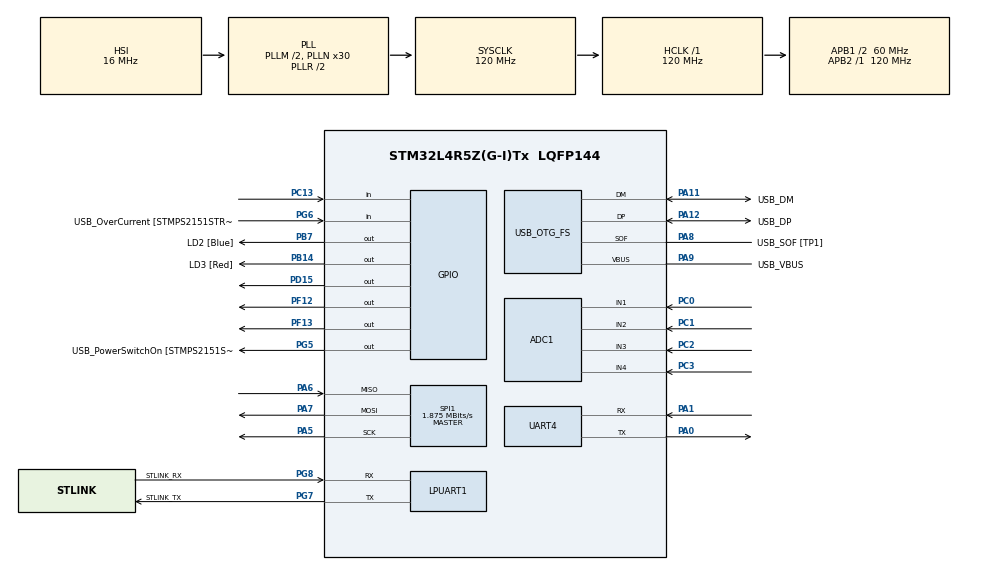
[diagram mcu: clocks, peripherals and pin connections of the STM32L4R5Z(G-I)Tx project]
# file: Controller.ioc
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ADC1.Channel-0\#ChannelRegularConversion=ADC_CHANNEL_1
ADC1.NbrOfConversionFlag=1
ADC1.OffsetNumber-0\#ChannelRegularConversion=ADC_OFFSET_NONE
ADC1.Rank-0\#ChannelRegularConversion=1
ADC1.SamplingTime-0\#ChannelRegularConversion=ADC_SAMPLETIME_2CYCLES_5
ADC1.master=1
Mcu.Family=STM32L4
Mcu.Name=STM32L4R5Z(G-I)Tx
Mcu.Package=LQFP144
NVIC.PriorityGroup=NVIC_PRIORITYGROUP_4
NVIC.TIM3_IRQn=true\:0\:0\:false\:false\:true\:true\:true\:true
PA0.Mode=Asynchronous
PA0.Signal=UART4_TX
PA1.Mode=Asynchronous
PA1.Signal=UART4_RX
PA10.GPIO_Label=USB_ID
PA10.Signal=USB_OTG_FS_ID
PA11.GPIO_Label=USB_DM
PA11.Mode=Device_Only
PA11.Signal=USB_OTG_FS_DM
PA12.GPIO_Label=USB_DP
PA12.Mode=Device_Only
PA12.Signal=USB_OTG_FS_DP
PA13\ (JTMS/SWDIO).GPIO_Label=TMS
PA13\ (JTMS/SWDIO).Mode=Trace_Asynchronous_SW
PA13\ (JTMS/SWDIO).Signal=SYS_JTMS-SWDIO
PA14\ (JTCK/SWCLK).GPIO_Label=TCK
PA14\ (JTCK/SWCLK).Mode=Trace_Asynchronous_SW
PA14\ (JTCK/SWCLK).Signal=SYS_JTCK-SWCLK
PA5.Mode=Full_Duplex_Master
PA5.Signal=SPI1_SCK
PA6.Mode=Full_Duplex_Master
PA6.Signal=SPI1_MISO
PA7.Mode=Full_Duplex_Master
PA7.Signal=SPI1_MOSI
PA8.GPIO_Label=USB_SOF [TP1]
PA8.Mode=Activate_SOF_FS
PA8.Signal=USB_OTG_FS_SOF
PA9.GPIO_Label=USB_VBUS
PA9.Mode=Activate_VBUS
PA9.Signal=USB_OTG_FS_VBUS
PB14.GPIO_Label=LD3 [Red]
PB14.Signal=GPIO_Output
PB3\ (JTDO/TRACESWO).GPIO_Label=SWO
PB3\ (JTDO/TRACESWO).Mode=Trace_Asynchronous_SW
PB3\ (JTDO/TRACESWO).Signal=SYS_JTDO-SWO
PB7.GPIO_Label=LD2 [Blue]
PB7.Signal=GPIO_Output
PC0.Signal=ADCx_IN1
PC1.Signal=ADCx_IN2
PC13.Signal=GPIO_Input
PC14-OSC32_IN\ (PC14).Mode=LSE-External-Oscillator
PC14-OSC32_IN\ (PC14).Signal=RCC_OSC32_IN
PC15-OSC32_OUT\ (PC15).Mode=LSE-External-Oscillator
PC15-OSC32_OUT\ (PC15).Signal=RCC_OSC32_OUT
PC2.Signal=ADCx_IN3
PC3.Signal=ADCx_IN4
PD15.Signal=GPIO_Output
PD8.GPIO_Label=STLK_RX [STM32F103CBT6_PA3]
PD8.Signal=USART3_TX
PD9.GPIO_Label=STLK_TX [STM32F103CBT6_PA2]
PD9.Signal=USART3_RX
PF12.PinState=GPIO_PIN_SET
PF12.Signal=GPIO_Output
PF13.PinState=GPIO_PIN_SET
PF13.Signal=GPIO_Output
PG5.GPIO_Label=USB_PowerSwitchOn [STMPS2151STR_EN]
PG5.Signal=GPIO_Output
PG6.GPIO_Label=USB_OverCurrent [STMPS2151STR_FAULT]
PG6.Signal=GPIO_Input
PG7.GPIO_Label=STLINK_TX
PG7.Mode=Asynchronous
PG7.Signal=LPUART1_TX
PG8.GPIO_Label=STLINK_RX
PG8.Mode=Asynchronous
PG8.Signal=LPUART1_RX
PH0-OSC_IN\ (PH0).Signal=RCC_OSC_IN
PH1-OSC_OUT\ (PH1).Signal=RCC_OSC_OUT
ProjectManager.HeapSize=0x200
ProjectManager.StackSize=0x400
ProjectManager.TargetToolchain=STM32CubeIDE
RCC.48MHZClocksFreq_Value=24000000
RCC.ADCFreq_Value=48000000
RCC.AHBFreq_Value=120000000
RCC.APB1CLKDivider=RCC_HCLK_DIV2
RCC.APB1Freq_Value=60000000
RCC.APB1TimFreq_Value=120000000
RCC.APB2Freq_Value=120000000
RCC.APB2TimFreq_Value=120000000
RCC.CK48CLockSelection=RCC_USBCLKSOURCE_HSI48
RCC.CortexFreq_Value=120000000
RCC.HCLKFreq_Value=120000000
RCC.HSE_VALUE=8000000
RCC.HSI48_VALUE=48000000
RCC.HSI_VALUE=16000000
RCC.MSI_VALUE=4000000
RCC.PLLM1=2
RCC.PLLM2=2
RCC.PLLMUL=RCC_PLL_MUL9
RCC.PLLN=30
RCC.PLLSAI1N=12
RCC.PLLSourceVirtual=RCC_PLLSOURCE_HSI
RCC.PRESCALERUSB=RCC_USBCLKSOURCE_PLL_DIV1_5
RCC.SYSCLKFreq_VALUE=120000000
RCC.SYSCLKSource=RCC_SYSCLKSOURCE_PLLCLK
RCC.SYSCLKSourceVirtual=RCC_SYSCLKSOURCE_PLLCLK
RCC.USBFreq_Value=48000000
RCC.VCOOutputFreq_Value=240000000
SH.ADCx_IN1.0=ADC1_IN1,IN1-Single-Ended
SH.ADCx_IN2.0=ADC1_IN2,IN2-Single-Ended
SH.ADCx_IN3.0=ADC1_IN3,IN3-Single-Ended
SH.ADCx_IN4.0=ADC1_IN4,IN4-Single-Ended
SPI1.BaudRatePrescaler=SPI_BAUDRATEPRESCALER_64
SPI1.CalculateBaudRate=1.875 MBits/s
SPI1.DataSize=SPI_DATASIZE_8BIT
SPI1.Direction=SPI_DIRECTION_2LINES
SPI1.Mode=SPI_MODE_MASTER
SPI1.NSSPMode=SPI_NSS_PULSE_DISABLE
SPI1.VirtualType=VM_MASTER
TIM3.Period=49999
TIM3.Prescaler=8399
UART4.FIFOMode=FIFOMODE_ENABLE
USB_OTG_FS.VirtualMode=Device_Only
VP_TIM3_VS_ClockSourceINT.Mode=Internal
board=NUCLEO-L4R5ZI

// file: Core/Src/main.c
/* USER CODE BEGIN Header */
/**
 ******************************************************************************
 * @file           : main.c
 * @brief          : Main program body
 ******************************************************************************
 * @attention
 *
 * Copyright (c) 2022 STMicroelectronics.
 * All rights reserved.
 *
 * This software is licensed under terms that can be found in the LICENSE file
 * in the root directory of this software component.
 * If no LICENSE file comes with this software, it is provided AS-IS.
 *
 ******************************************************************************
 */
/* USER CODE END Header */
#include "main.h"

/* USER CODE BEGIN Includes */
#include "LCD.h"
#include "TS.h"
#include <stdlib.h>
#include <math.h>
/* USER CODE END Includes */

/* USER CODE BEGIN PD */
#define COL_1			40
#define COL_2 		155
#define COL_3  	 	268
#define ROW_1			204
#define ROW_2			350
#define ROW_3			454
#define ERROR			25
/* USER CODE END PD */

ADC_HandleTypeDef hadc1;

UART_HandleTypeDef hlpuart1;
UART_HandleTypeDef huart4;

SPI_HandleTypeDef hspi1;

TIM_HandleTypeDef htim3;

PCD_HandleTypeDef hpcd_USB_OTG_FS;

/* USER CODE BEGIN PV */
unsigned char goalTemp[3][2];
unsigned char currTemp[3][2];
struct room {
	uint8_t goalTemp;
	uint8_t currTemp;
	uint8_t ID;
}typedef room_t;

void initRoom(room_t *room, int ID, int goalTemp, int currTemp) {
	room->ID = ID;
	room->goalTemp = goalTemp;
	room->currTemp = currTemp;
}

void initDisplay(SPI_HandleTypeDef *spi, room_t *rooms, int count) {
	LCD_writePixels(&hspi1, LCD_color565(255, 255, 255), 0, 0, LCD_WIDTH,
	LCD_HEIGHT);
	for (int i = 0; i < count; ++i) {
		itoa(rooms[i].goalTemp, &goalTemp[i][0], 10);
		itoa(rooms[i].currTemp, &currTemp[i][0], 10);

		int size = 8;
		int start = (LCD_WIDTH / 3) * (rooms[i].ID - 1) + size + 5;

		LCD_drawStringNoBG(spi, start, size, &currTemp[i][0], 2,
				LCD_color565(0, 0, 0), size);
		LCD_drawStringNoBG(spi, start, 9 * size, &goalTemp[i][0], 2,
				LCD_color565(75, 75, 75), size);

		LCD_drawButtonNoBG(&hspi1, start, 18 * size, 0, LCD_color565(255, 0, 0),
				size * 2 + 1);
		LCD_drawButtonNoBG(&hspi1, start, 34 * size, 1, LCD_color565(0, 0, 255),
				size * 2 + 1);
	}
	unsigned char heat[4] = "HEAT";
	unsigned char air[3] = "AIR";
	LCD_writePixels(&hspi1, LCD_color565(0, 0, 0), 6, LCD_HEIGHT - 8 * 6 - 4,
			23 * 6, 2);
	LCD_drawStringNoBG(spi, 6, LCD_HEIGHT - 8 * 6, &heat[0], 4,
			LCD_color565(0, 0, 0), 6);
	LCD_drawStringNoBG(spi, LCD_WIDTH - 18 * 6, LCD_HEIGHT - 8 * 6, &air[0], 3,
			LCD_color565(0, 0, 0), 6);
}

void updateDisplayTemp(SPI_HandleTypeDef *spi, room_t *room) {
	unsigned char buf[2];
	int size = 8;
	int start = (LCD_WIDTH / 3) * (room->ID - 1) + size + 5;

	itoa(room->currTemp, &buf[0], 10);
	if (buf[0] != currTemp[room->ID - 1][0]) {
		LCD_drawStringOPT(spi, start, size, &buf[0], &currTemp[room->ID - 1][0],
				2, LCD_color565(0, 0, 0), size);
		currTemp[room->ID - 1][0] = buf[0];
		currTemp[room->ID - 1][1] = buf[1];
	} else if (buf[1] != currTemp[room->ID - 1][1]) {
		LCD_drawCharOPT(spi, start + 6 * size, size, buf[1],
				currTemp[room->ID - 1][1], LCD_color565(0, 0, 0), size);
		currTemp[room->ID - 1][1] = buf[1];
	}

	itoa(room->goalTemp, &buf[0], 10);
	if (buf[0] != goalTemp[room->ID - 1][0]) {
		LCD_drawStringOPT(spi, start, 9 * size, &buf[0],
				&goalTemp[room->ID - 1][0], 2, LCD_color565(75, 75, 75), size);
		goalTemp[room->ID - 1][0] = buf[0];
		goalTemp[room->ID - 1][1] = buf[1];
	} else if (buf[1] != goalTemp[room->ID - 1][1]) {
		LCD_drawCharOPT(spi, start + 6 * size, 9 * size, buf[1],
				goalTemp[room->ID - 1][1], LCD_color565(75, 75, 75), size);
		goalTemp[room->ID - 1][1] = buf[1];
	}
}

void updateDisplayFurnace(SPI_HandleTypeDef *spi, int furnaceState) {
	int size = 6;
	if (furnaceState) {
		LCD_writePixels(spi, LCD_color565(255, 255, 255), size,
		LCD_HEIGHT - 8 * 6 - 4, 23 * size, 2);
		LCD_writePixels(&hspi1, LCD_color565(0, 0, 0), LCD_WIDTH - 18 * 6,
		LCD_HEIGHT - 8 * 6 - 4, 17 * size, 2);
	} else {
		LCD_writePixels(spi, LCD_color565(0, 0, 0), size,
		LCD_HEIGHT - 8 * 6 - 4, 23 * size, 2);
		LCD_writePixels(&hspi1, LCD_color565(255, 255, 255), LCD_WIDTH - 18 * 6,
		LCD_HEIGHT - 8 * 6 - 4, 17 * size, 2);
	}
}
/* USER CODE END PV */

void SystemClock_Config(void);
static void MX_GPIO_Init(void);
static void MX_LPUART1_UART_Init(void);
static void MX_USB_OTG_FS_PCD_Init(void);
static void MX_ADC1_Init(void);
static void MX_SPI1_Init(void);
static void MX_UART4_Init(void);
static void MX_TIM3_Init(void);

/* USER CODE BEGIN 0 */
uint8_t curr_temp[] = { 0, 0, 0, 0 };
uint8_t desired_temp[] = { 0, 11, 11, 0 };

HAL_StatusTypeDef transmit_status;
HAL_StatusTypeDef receive_status;

int interrupts_disabled = 0;
room_t rooms[3];

/* {0x00000000, 0x00000000} - ([0] => either 0 for desired state command, or a 1 for peripheral current_temp request command),
 *							([1] => first bit is furnace status, next 5 are desired temp, last 2 are vent id) */
uint8_t data_size = 2;
uint8_t received_data_size = 1;
uint8_t send_desired_state = 0x00;
uint8_t receive_current_temp = 0x80;
uint8_t furnace_status_on = 0x80;
uint8_t furnace_status_off = 0x00;
uint8_t vent_id_1 = 0x01;
uint8_t vent_id_2 = 0x02;
uint8_t vent_id_3 = 0x03;
uint8_t vent_ids[] = { 0x00, 0x01, 0x02, 0x03 };

HAL_StatusTypeDef transmit_updated_state(uint8_t data) {
	HAL_StatusTypeDef transmit_status = HAL_UART_Transmit(&huart4, data, 1,
			100);
	return transmit_status;
}

HAL_StatusTypeDef receive_acknowledge(uint8_t *received_data) {
	HAL_StatusTypeDef receive_status = HAL_UART_Receive(&huart4, received_data,
			1, 100);
	return receive_status;
}

void transmit_room_info(uint8_t *received_data, uint8_t room_index) {
	while (receive_acknowledge(received_data) != HAL_OK) {
		uint8_t lower_temp = ((rooms[room_index].goalTemp & 0x0F) << 4) | rooms[room_index].ID;
		transmit_updated_state(lower_temp);
	}
	while (receive_acknowledge(received_data) != HAL_OK) {
		uint8_t upper_temp = (rooms[room_index].goalTemp & 0xF0) | rooms[room_index].ID;
		transmit_updated_state(upper_temp);
	}
	while (receive_acknowledge(received_data) != HAL_OK) {
		transmit_updated_state((furnaceState << 5) | rooms[room_index].ID);
	}
}

//HAL_StatusTypeDef transmit_updated_state(room_t *rooms, int furnace_status) {
//	HAL_StatusTypeDef transmit_status;
//	uint8_t data[] = { send_desired_state, (uint8_t) ((furnace_status << 7)
//			| ((rooms->goalTemp - 55) << 2) | rooms->ID) };
//	for (int j = 0; j < sizeof(data); j++) {
//		transmit_status = HAL_UART_Transmit(&huart4, &(data[j]), 1, 1000);
//	}
//	HAL_Delay(1000);
//	return transmit_status;
//}

/* USER CODE END 0 */

int main(void) {

	/* MCU Configuration--------------------------------------------------------*/

	/* Reset of all peripherals, Initializes the Flash interface and the Systick. */
	HAL_Init();

	/* Configure the system clock */
	SystemClock_Config();

	/* Initialize all configured peripherals */
	MX_GPIO_Init();
	MX_LPUART1_UART_Init();
	MX_USB_OTG_FS_PCD_Init();
	MX_ADC1_Init();
	MX_SPI1_Init();
	MX_UART4_Init();
	MX_TIM3_Init();
	/* USER CODE BEGIN 2 */
	int res = LCD_begin(&hspi1);
	for (int i = 0; i < 3; ++i)
		initRoom(&rooms[i], i + 1, 70, 65);
	initDisplay(&hspi1, &rooms[0], 3);

	/* USER CODE END 2 */

	/* Infinite loop */
	/* USER CODE BEGIN WHILE */
	int furnaceState = 0;
	double x, y, z;
	double X, Y;
	while (1) {
		/* USER CODE END WHILE */

		/* USER CODE BEGIN 3 */
		uint8_t received_data[1];

		z = TS_readPressure(&hadc1);
		x = TS_readX(&hadc1);
		y = TS_readY(&hadc1);

		if (z < 1000) {
			transform(x, y, &X, &Y);
			int newGoal1 = 0, newGoal2 = 0, newGoal3 = 0, newFurnace = 0;
			if (X > COL_1 - ERROR && X < COL_1 + ERROR) {
				if (Y > ROW_1 - ERROR && Y < ROW_1 + ERROR) {
					rooms[0].goalTemp += 1;
					newGoal1 = 1;
				} else if (Y > ROW_2 - ERROR && Y < ROW_2 + ERROR) {
					rooms[0].goalTemp -= 1;
					newGoal1 = 1;
				} else if (Y > ROW_3 - ERROR && Y < ROW_3 + ERROR) {
					furnaceState = 0;
					newFurnace = 1;
				}
			} else if (X > COL_2 - ERROR && X < COL_2 + ERROR) {
				if (Y > ROW_1 - ERROR && Y < ROW_1 + ERROR) {
					rooms[1].goalTemp += 1;
					newGoal2 = 1;
				} else if (Y > ROW_2 - ERROR && Y < ROW_2 + ERROR) {
					rooms[1].goalTemp -= 1;
					newGoal2 = 1;
				}
			} else if (X > COL_3 - ERROR && X < COL_3 + ERROR) {
				if (Y > ROW_1 - ERROR && Y < ROW_1 + ERROR) {
					rooms[2].goalTemp += 1;
					newGoal3 = 1;
				} else if (Y > ROW_2 - ERROR && Y < ROW_2 + ERROR) {
					rooms[2].goalTemp -= 1;
					newGoal3 = 1;
				} else if (Y > ROW_3 - ERROR && Y < ROW_3 + ERROR) {
					furnaceState = 1;
					newFurnace = 1;
				}
			}

			for (int i = 0; i < 3; ++i) {
				rooms[i].goalTemp =
						(rooms[i].goalTemp < 99) ? rooms[i].goalTemp : 99;
				rooms[i].goalTemp =
						(rooms[i].goalTemp > 0) ? rooms[i].goalTemp : 0;
				rooms[i].currTemp =
						(rooms[i].currTemp < 99) ? rooms[i].currTemp : 99;
				rooms[i].currTemp =
						(rooms[i].currTemp > 0) ? rooms[i].currTemp : 0;
			}

			if (newGoal1) {
				interrupts_disabled = 1;
				transmit_room_info(received_data, 0);
				interrupts_disabled = 0;
				updateDisplayTemp(&hspi1, &rooms[0]);
			}
			if (newGoal2) {
				interrupts_disabled = 1;
				transmit_room_info(received_data, 1);
				interrupts_disabled = 0;
				updateDisplayTemp(&hspi1, &rooms[1]);
			}
			if (newGoal3) {
				interrupts_disabled = 1;
				transmit_room_info(received_data, 2);
				interrupts_disabled = 0;
				updateDisplayTemp(&hspi1, &rooms[2]);
			}
			if (newFurnace) {
				interrupts_disabled = 1;
				transmit_room_info(received_data, 0);
				transmit_room_info(received_data, 1);
				transmit_room_info(received_data, 2);
				interrupts_disabled = 0;
				updateDisplayFurnace(&hspi1, furnaceState);
			}
		}

//	  GPIO_PinState pin_state = HAL_GPIO_ReadPin(GPIOC, GPIO_PIN_13);

//	  if(pin_state){
//		  for(int i = 0; i < sizeof(data); i++){
//			  transmit_status = HAL_UART_Transmit(&huart4, &(data[i]), 1, 1000);
//		  }
//		  transmit_status = HAL_UART_Transmit(&huart4, data, sizeof(data), 100);
//	  }

//	  for(int i = sizeof(received_data) - 1; i >= 0; i--){
//		  receive_status = HAL_UART_Receive(&huart4, &(received_data[i]), 1, 1000);
//	  }
//	  receive_status = HAL_UART_Receive(&huart4, received_data, sizeof(received_data), 100);

//	  if(received_data[0] == 31 && receive_status == HAL_OK){
//		  HAL_GPIO_WritePin(GPIOB, GPIO_PIN_7,  GPIO_PIN_SET);
//		  HAL_Delay(1000);
//		  HAL_GPIO_WritePin(GPIOB, GPIO_PIN_7,  GPIO_PIN_RESET);
//	  } else {
//		  HAL_GPIO_WritePin(GPIOB, GPIO_PIN_7,  GPIO_PIN_RESET);
//	  }

//	  if(received_data[0] == 0x41){
//		  HAL_GPIO_WritePin(GPIOB, GPIO_PIN_7,  GPIO_PIN_SET);
//		  HAL_Delay(1000);
//		  HAL_GPIO_WritePin(GPIOB, GPIO_PIN_7,  GPIO_PIN_RESET);
//	  } else if(received_data[0] == 0x42){
//		  HAL_GPIO_WritePin(GPIOB, GPIO_PIN_7,  GPIO_PIN_SET);
//		  HAL_Delay(1000);
//		  HAL_GPIO_WritePin(GPIOB, GPIO_PIN_7,  GPIO_PIN_RESET);
//		  HAL_Delay(1000);
//		  HAL_GPIO_WritePin(GPIOB, GPIO_PIN_7,  GPIO_PIN_SET);
//		  HAL_Delay(1000);
//		  HAL_GPIO_WritePin(GPIOB, GPIO_PIN_7,  GPIO_PIN_RESET);
//	  } else if(received_data[0] == 0x43){
//		  HAL_GPIO_WritePin(GPIOB, GPIO_PIN_7,  GPIO_PIN_SET);
//		  HAL_Delay(1000);
//		  HAL_GPIO_WritePin(GPIOB, GPIO_PIN_7,  GPIO_PIN_RESET);
//		  HAL_Delay(1000);
//		  HAL_GPIO_WritePin(GPIOB, GPIO_PIN_7,  GPIO_PIN_SET);
//		  HAL_Delay(1000);
//		  HAL_GPIO_WritePin(GPIOB, GPIO_PIN_7,  GPIO_PIN_RESET);
//		  HAL_Delay(1000);
//		  HAL_GPIO_WritePin(GPIOB, GPIO_PIN_7,  GPIO_PIN_SET);
//		  HAL_Delay(1000);
//		  HAL_GPIO_WritePin(GPIOB, GPIO_PIN_7,  GPIO_PIN_RESET);
//	  } else {
//		  HAL_GPIO_WritePin(GPIOB, GPIO_PIN_7,  GPIO_PIN_RESET);
//	  }

		HAL_Delay(10);

	}
	/* USER CODE END 3 */
}

void SystemClock_Config(void) {
	RCC_OscInitTypeDef RCC_OscInitStruct = { 0 };
	RCC_ClkInitTypeDef RCC_ClkInitStruct = { 0 };

	/** Configure the main internal regulator output voltage
	 */
	if (HAL_PWREx_ControlVoltageScaling(PWR_REGULATOR_VOLTAGE_SCALE1_BOOST)
			!= HAL_OK) {
		Error_Handler();
	}

	/** Initializes the RCC Oscillators according to the specified parameters
	 * in the RCC_OscInitTypeDef structure.
	 */
	RCC_OscInitStruct.OscillatorType = RCC_OSCILLATORTYPE_HSI48
			| RCC_OSCILLATORTYPE_HSI;
	RCC_OscInitStruct.HSIState = RCC_HSI_ON;
	RCC_OscInitStruct.HSI48State = RCC_HSI48_ON;
	RCC_OscInitStruct.HSICalibrationValue = RCC_HSICALIBRATION_DEFAULT;
	RCC_OscInitStruct.PLL.PLLState = RCC_PLL_ON;
	RCC_OscInitStruct.PLL.PLLSource = RCC_PLLSOURCE_HSI;
	RCC_OscInitStruct.PLL.PLLM = 2;
	RCC_OscInitStruct.PLL.PLLN = 30;
	RCC_OscInitStruct.PLL.PLLP = RCC_PLLP_DIV2;
	RCC_OscInitStruct.PLL.PLLQ = RCC_PLLQ_DIV2;
	RCC_OscInitStruct.PLL.PLLR = RCC_PLLR_DIV2;
	if (HAL_RCC_OscConfig(&RCC_OscInitStruct) != HAL_OK) {
		Error_Handler();
	}

	/** Initializes the CPU, AHB and APB buses clocks
	 */
	RCC_ClkInitStruct.ClockType = RCC_CLOCKTYPE_HCLK | RCC_CLOCKTYPE_SYSCLK
			| RCC_CLOCKTYPE_PCLK1 | RCC_CLOCKTYPE_PCLK2;
	RCC_ClkInitStruct.SYSCLKSource = RCC_SYSCLKSOURCE_PLLCLK;
	RCC_ClkInitStruct.AHBCLKDivider = RCC_SYSCLK_DIV1;
	RCC_ClkInitStruct.APB1CLKDivider = RCC_HCLK_DIV2;
	RCC_ClkInitStruct.APB2CLKDivider = RCC_HCLK_DIV1;

	if (HAL_RCC_ClockConfig(&RCC_ClkInitStruct, FLASH_LATENCY_5) != HAL_OK) {
		Error_Handler();
	}
}

static void MX_ADC1_Init(void) {

	ADC_ChannelConfTypeDef sConfig = { 0 };

	/** Common config
	 */
	hadc1.Instance = ADC1;
	hadc1.Init.ClockPrescaler = ADC_CLOCK_ASYNC_DIV12;
	hadc1.Init.Resolution = ADC_RESOLUTION_12B;
	hadc1.Init.DataAlign = ADC_DATAALIGN_RIGHT;
	hadc1.Init.ScanConvMode = ADC_SCAN_DISABLE;
	hadc1.Init.EOCSelection = ADC_EOC_SINGLE_CONV;
	hadc1.Init.LowPowerAutoWait = DISABLE;
	hadc1.Init.ContinuousConvMode = DISABLE;
	hadc1.Init.NbrOfConversion = 1;
	hadc1.Init.DiscontinuousConvMode = DISABLE;
	hadc1.Init.ExternalTrigConv = ADC_SOFTWARE_START;
	hadc1.Init.ExternalTrigConvEdge = ADC_EXTERNALTRIGCONVEDGE_NONE;
	hadc1.Init.DMAContinuousRequests = DISABLE;
	hadc1.Init.Overrun = ADC_OVR_DATA_PRESERVED;
	hadc1.Init.OversamplingMode = DISABLE;
	if (HAL_ADC_Init(&hadc1) != HAL_OK) {
		Error_Handler();
	}

	/** Configure Regular Channel
	 */
	sConfig.Channel = ADC_CHANNEL_1;
	sConfig.Rank = ADC_REGULAR_RANK_1;
	sConfig.SamplingTime = ADC_SAMPLETIME_640CYCLES_5;
	sConfig.SingleDiff = ADC_SINGLE_ENDED;
	sConfig.OffsetNumber = ADC_OFFSET_NONE;
	sConfig.Offset = 0;
	if (HAL_ADC_ConfigChannel(&hadc1, &sConfig) != HAL_OK) {
		Error_Handler();
	}

}

static void MX_LPUART1_UART_Init(void) {

	hlpuart1.Instance = LPUART1;
	hlpuart1.Init.BaudRate = 209700;
	hlpuart1.Init.WordLength = UART_WORDLENGTH_7B;
	hlpuart1.Init.StopBits = UART_STOPBITS_1;
	hlpuart1.Init.Parity = UART_PARITY_NONE;
	hlpuart1.Init.Mode = UART_MODE_TX_RX;
	hlpuart1.Init.HwFlowCtl = UART_HWCONTROL_NONE;
	hlpuart1.Init.OneBitSampling = UART_ONE_BIT_SAMPLE_DISABLE;
	hlpuart1.Init.ClockPrescaler = UART_PRESCALER_DIV1;
	hlpuart1.AdvancedInit.AdvFeatureInit = UART_ADVFEATURE_NO_INIT;
	hlpuart1.FifoMode = UART_FIFOMODE_DISABLE;
	if (HAL_UART_Init(&hlpuart1) != HAL_OK) {
		Error_Handler();
	}
	if (HAL_UARTEx_SetTxFifoThreshold(&hlpuart1, UART_TXFIFO_THRESHOLD_1_8)
			!= HAL_OK) {
		Error_Handler();
	}
	if (HAL_UARTEx_SetRxFifoThreshold(&hlpuart1, UART_RXFIFO_THRESHOLD_1_8)
			!= HAL_OK) {
		Error_Handler();
	}
	if (HAL_UARTEx_DisableFifoMode(&hlpuart1) != HAL_OK) {
		Error_Handler();
	}

}

static void MX_UART4_Init(void) {

	huart4.Instance = UART4;
	huart4.Init.BaudRate = 115200;
	huart4.Init.WordLength = UART_WORDLENGTH_8B;
	huart4.Init.StopBits = UART_STOPBITS_1;
	huart4.Init.Parity = UART_PARITY_NONE;
	huart4.Init.Mode = UART_MODE_TX_RX;
	huart4.Init.HwFlowCtl = UART_HWCONTROL_NONE;
	huart4.Init.OverSampling = UART_OVERSAMPLING_16;
	huart4.Init.OneBitSampling = UART_ONE_BIT_SAMPLE_DISABLE;
	huart4.Init.ClockPrescaler = UART_PRESCALER_DIV1;
	huart4.AdvancedInit.AdvFeatureInit = UART_ADVFEATURE_NO_INIT;
	if (HAL_UART_Init(&huart4) != HAL_OK) {
		Error_Handler();
	}
	if (HAL_UARTEx_SetTxFifoThreshold(&huart4, UART_TXFIFO_THRESHOLD_1_8)
			!= HAL_OK) {
		Error_Handler();
	}
	if (HAL_UARTEx_SetRxFifoThreshold(&huart4, UART_RXFIFO_THRESHOLD_1_8)
			!= HAL_OK) {
		Error_Handler();
	}
	if (HAL_UARTEx_EnableFifoMode(&huart4) != HAL_OK) {
		Error_Handler();
	}

}

static void MX_SPI1_Init(void) {

	/* SPI1 parameter configuration*/
	hspi1.Instance = SPI1;
	hspi1.Init.Mode = SPI_MODE_MASTER;
	hspi1.Init.Direction = SPI_DIRECTION_2LINES;
	hspi1.Init.DataSize = SPI_DATASIZE_8BIT;
	hspi1.Init.CLKPolarity = SPI_POLARITY_LOW;
	hspi1.Init.CLKPhase = SPI_PHASE_1EDGE;
	hspi1.Init.NSS = SPI_NSS_SOFT;
	hspi1.Init.BaudRatePrescaler = SPI_BAUDRATEPRESCALER_64;
	hspi1.Init.FirstBit = SPI_FIRSTBIT_MSB;
	hspi1.Init.TIMode = SPI_TIMODE_DISABLE;
	hspi1.Init.CRCCalculation = SPI_CRCCALCULATION_DISABLE;
	hspi1.Init.CRCPolynomial = 7;
	hspi1.Init.CRCLength = SPI_CRC_LENGTH_DATASIZE;
	hspi1.Init.NSSPMode = SPI_NSS_PULSE_DISABLE;
	if (HAL_SPI_Init(&hspi1) != HAL_OK) {
		Error_Handler();
	}

}

static void MX_TIM3_Init(void) {

	TIM_ClockConfigTypeDef sClockSourceConfig = { 0 };
	TIM_MasterConfigTypeDef sMasterConfig = { 0 };

	htim3.Instance = TIM3;
	htim3.Init.Prescaler = 8399;
	htim3.Init.CounterMode = TIM_COUNTERMODE_UP;
	htim3.Init.Period = 49999;
	htim3.Init.ClockDivision = TIM_CLOCKDIVISION_DIV1;
	htim3.Init.AutoReloadPreload = TIM_AUTORELOAD_PRELOAD_DISABLE;
	if (HAL_TIM_Base_Init(&htim3) != HAL_OK) {
		Error_Handler();
	}
	sClockSourceConfig.ClockSource = TIM_CLOCKSOURCE_INTERNAL;
	if (HAL_TIM_ConfigClockSource(&htim3, &sClockSourceConfig) != HAL_OK) {
		Error_Handler();
	}
	sMasterConfig.MasterOutputTrigger = TIM_TRGO_RESET;
	sMasterConfig.MasterSlaveMode = TIM_MASTERSLAVEMODE_DISABLE;
	if (HAL_TIMEx_MasterConfigSynchronization(&htim3, &sMasterConfig)
			!= HAL_OK) {
		Error_Handler();
	}

}

static void MX_USB_OTG_FS_PCD_Init(void) {

	hpcd_USB_OTG_FS.Instance = USB_OTG_FS;
	hpcd_USB_OTG_FS.Init.dev_endpoints = 6;
	hpcd_USB_OTG_FS.Init.phy_itface = PCD_PHY_EMBEDDED;
	hpcd_USB_OTG_FS.Init.Sof_enable = ENABLE;
	hpcd_USB_OTG_FS.Init.low_power_enable = DISABLE;
	hpcd_USB_OTG_FS.Init.lpm_enable = DISABLE;
	hpcd_USB_OTG_FS.Init.battery_charging_enable = ENABLE;
	hpcd_USB_OTG_FS.Init.use_dedicated_ep1 = DISABLE;
	hpcd_USB_OTG_FS.Init.vbus_sensing_enable = ENABLE;
	if (HAL_PCD_Init(&hpcd_USB_OTG_FS) != HAL_OK) {
		Error_Handler();
	}

}

static void MX_GPIO_Init(void) {
	GPIO_InitTypeDef GPIO_InitStruct = { 0 };

	/* GPIO Ports Clock Enable */
	__HAL_RCC_GPIOC_CLK_ENABLE();
	__HAL_RCC_GPIOH_CLK_ENABLE();
	__HAL_RCC_GPIOA_CLK_ENABLE();
	__HAL_RCC_GPIOF_CLK_ENABLE();
	__HAL_RCC_GPIOB_CLK_ENABLE();
	__HAL_RCC_GPIOD_CLK_ENABLE();
	__HAL_RCC_GPIOG_CLK_ENABLE();
	HAL_PWREx_EnableVddIO2();

	/*Configure GPIO pin Output Level */
	HAL_GPIO_WritePin(GPIOF, GPIO_PIN_12 | GPIO_PIN_13, GPIO_PIN_SET);

	/*Configure GPIO pin Output Level */
	HAL_GPIO_WritePin(GPIOF, GPIO_PIN_14, GPIO_PIN_RESET);

	/*Configure GPIO pin Output Level */
	HAL_GPIO_WritePin(GPIOB, LD3_Pin | LD2_Pin, GPIO_PIN_RESET);

	/*Configure GPIO pin Output Level */
	HAL_GPIO_WritePin(GPIOD, GPIO_PIN_15, GPIO_PIN_RESET);

	/*Configure GPIO pin Output Level */
	HAL_GPIO_WritePin(USB_PowerSwitchOn_GPIO_Port, USB_PowerSwitchOn_Pin,
			GPIO_PIN_RESET);

	/*Configure GPIO pin : PC13 */
	GPIO_InitStruct.Pin = GPIO_PIN_13;
	GPIO_InitStruct.Mode = GPIO_MODE_INPUT;
	GPIO_InitStruct.Pull = GPIO_NOPULL;
	HAL_GPIO_Init(GPIOC, &GPIO_InitStruct);

	/*Configure GPIO pins : PF12 PF13 PF14 */
	GPIO_InitStruct.Pin = GPIO_PIN_12 | GPIO_PIN_13 | GPIO_PIN_14;
	GPIO_InitStruct.Mode = GPIO_MODE_OUTPUT_PP;
	GPIO_InitStruct.Pull = GPIO_NOPULL;
	GPIO_InitStruct.Speed = GPIO_SPEED_FREQ_LOW;
	HAL_GPIO_Init(GPIOF, &GPIO_InitStruct);

	/*Configure GPIO pins : LD3_Pin LD2_Pin */
	GPIO_InitStruct.Pin = LD3_Pin | LD2_Pin;
	GPIO_InitStruct.Mode = GPIO_MODE_OUTPUT_PP;
	GPIO_InitStruct.Pull = GPIO_NOPULL;
	GPIO_InitStruct.Speed = GPIO_SPEED_FREQ_LOW;
	HAL_GPIO_Init(GPIOB, &GPIO_InitStruct);

	/*Configure GPIO pins : STLK_RX_Pin STLK_TX_Pin */
	GPIO_InitStruct.Pin = STLK_RX_Pin | STLK_TX_Pin;
	GPIO_InitStruct.Mode = GPIO_MODE_AF_PP;
	GPIO_InitStruct.Pull = GPIO_NOPULL;
	GPIO_InitStruct.Speed = GPIO_SPEED_FREQ_VERY_HIGH;
	GPIO_InitStruct.Alternate = GPIO_AF7_USART3;
	HAL_GPIO_Init(GPIOD, &GPIO_InitStruct);

	/*Configure GPIO pin : PD15 */
	GPIO_InitStruct.Pin = GPIO_PIN_15;
	GPIO_InitStruct.Mode = GPIO_MODE_OUTPUT_PP;
	GPIO_InitStruct.Pull = GPIO_NOPULL;
	GPIO_InitStruct.Speed = GPIO_SPEED_FREQ_LOW;
	HAL_GPIO_Init(GPIOD, &GPIO_InitStruct);

	/*Configure GPIO pin : USB_PowerSwitchOn_Pin */
	GPIO_InitStruct.Pin = USB_PowerSwitchOn_Pin;
	GPIO_InitStruct.Mode = GPIO_MODE_OUTPUT_PP;
	GPIO_InitStruct.Pull = GPIO_NOPULL;
	GPIO_InitStruct.Speed = GPIO_SPEED_FREQ_LOW;
	HAL_GPIO_Init(USB_PowerSwitchOn_GPIO_Port, &GPIO_InitStruct);

	/*Configure GPIO pin : USB_OverCurrent_Pin */
	GPIO_InitStruct.Pin = USB_OverCurrent_Pin;
	GPIO_InitStruct.Mode = GPIO_MODE_INPUT;
	GPIO_InitStruct.Pull = GPIO_NOPULL;
	HAL_GPIO_Init(USB_OverCurrent_GPIO_Port, &GPIO_InitStruct);

}

/* USER CODE BEGIN 4 */
void HAL_TIM_PeriodElapsedCallback(TIM_HandleTypeDef *htim) {
	if (!interrupts_disabled) {
		if (htim == &htim3) {
			uint8_t received_data[1];

			transmit_room_info(received_data, 0);
			rooms[0].currTemp = received_data[0];
			transmit_room_info(received_data, 1);
			rooms[1].currTemp = received_data[0];
			transmit_room_info(received_data, 2);
			rooms[2].currTemp = received_data[0];

//			while (receive_acknowledge(received_data) != HAL_OK) {
//				transmit_updated_state(1);
//			}
//			rooms[0].currTemp = received_data[0];
//			while (receive_acknowledge(received_data) != HAL_OK) {
//				transmit_updated_state(2);
//			}
//			rooms[1].currTemp = received_data[0];
//			while (receive_acknowledge(received_data) != HAL_OK) {
//				transmit_updated_state(3);
//			}
//			rooms[2].currTemp = received_data[0];
		}
	}
}
/* USER CODE END 4 */

void Error_Handler(void) {
	__disable_irq();
	while (1) {
	}
}
